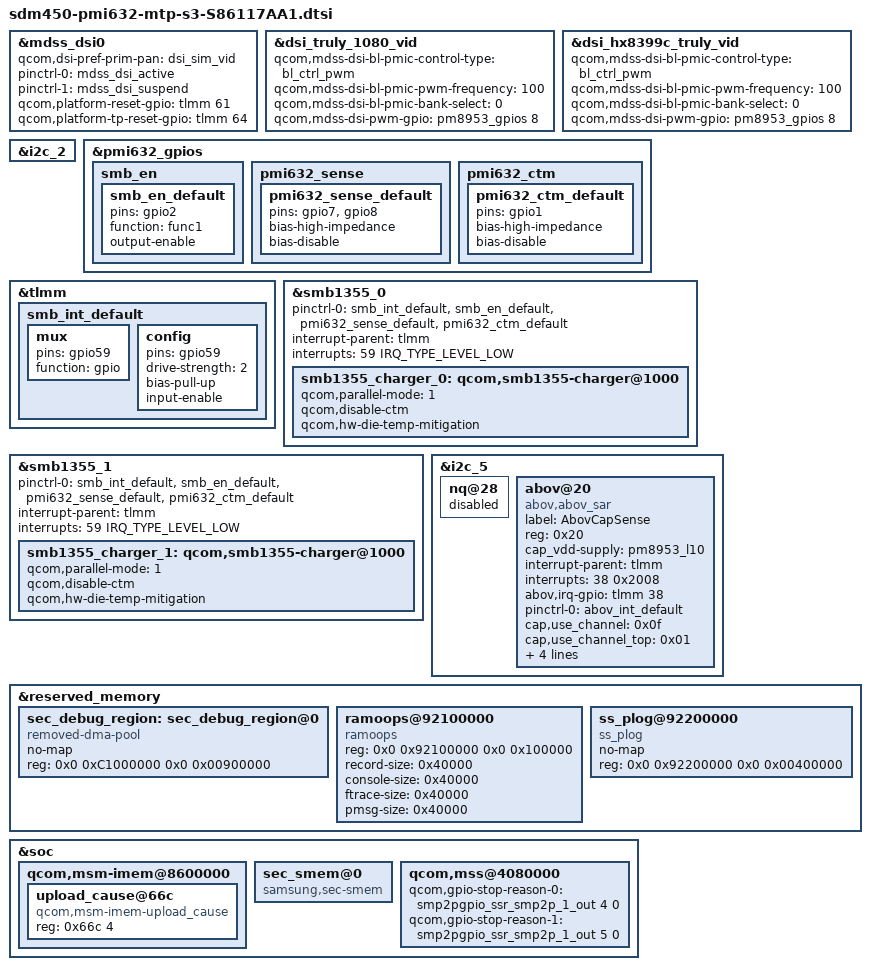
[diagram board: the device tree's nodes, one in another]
/*
 * Copyright (c) 2018-2019, The Linux Foundation. All rights reserved.
 *
 * This program is free software; you can redistribute it and/or modify
 * it under the terms of the GNU General Public License version 2 and
 * only version 2 as published by the Free Software Foundation.
 *
 * This program is distributed in the hope that it will be useful,
 * but WITHOUT ANY WARRANTY; without even the implied warranty of
 * MERCHANTABILITY or FITNESS FOR A PARTICULAR PURPOSE.  See the
 * GNU General Public License for more details.
 */

#include "msm8953-mtp.dtsi"

&mdss_dsi0 {
	qcom,dsi-pref-prim-pan = <&dsi_sim_vid>;
	pinctrl-names = "mdss_default", "mdss_sleep";
	pinctrl-0 = <&mdss_dsi_active>;
	pinctrl-1 = <&mdss_dsi_suspend>;
	//qcom,platform-bklight-en-gpio = <&pm8953_gpios 4 0>;
	qcom,platform-reset-gpio = <&tlmm 61 0>;
	qcom,platform-tp-reset-gpio = <&tlmm 64 0>;
};

&dsi_truly_1080_vid {
	qcom,mdss-dsi-bl-pmic-control-type = "bl_ctrl_pwm";
	qcom,mdss-dsi-bl-pmic-pwm-frequency = <100>;
	qcom,mdss-dsi-bl-pmic-bank-select = <0>;
	qcom,mdss-dsi-pwm-gpio = <&pm8953_gpios 8 0>;
};

&dsi_hx8399c_truly_vid {
	qcom,mdss-dsi-bl-pmic-control-type = "bl_ctrl_pwm";
	qcom,mdss-dsi-bl-pmic-pwm-frequency = <100>;
	qcom,mdss-dsi-bl-pmic-bank-select = <0>;
	qcom,mdss-dsi-pwm-gpio = <&pm8953_gpios 8 0>;
};

&i2c_2 {
#address-cells = <1>;
#size-cells = <0>;

#include "smb1355.dtsi"
};

&pmi632_gpios {
	smb_en {
		smb_en_default: smb_en_default {
			pins = "gpio2";
			function = "func1";
			output-enable;
		};
	};

	pmi632_sense {
		/* GPIO 7 and 8 are external-sense pins for PMI632 */
		pmi632_sense_default: pmi632_sense_default {
			pins = "gpio7", "gpio8";
			bias-high-impedance;	/* disable the GPIO */
			bias-disable;		/* no-pull */
		};
	};

	pmi632_ctm {
		/* Disable GPIO1 for h/w base mitigation */
		pmi632_ctm_default: pmi632_ctm_default {
			pins = "gpio1";
			bias-high-impedance;	/* disable the GPIO */
			bias-disable;		/* no-pull */
		};
	};
};

&tlmm {
	smb_int_default: smb_int_default {
		mux {
			pins = "gpio59";
			function = "gpio";
		};
		config {
			pins = "gpio59";
			drive-strength = <2>;
			bias-pull-up;
			input-enable;
		};
	};
};

&smb1355_0 {
	pinctrl-names = "default";
	pinctrl-0 = <&smb_int_default
		&smb_en_default &pmi632_sense_default &pmi632_ctm_default>;
	interrupt-parent = <&tlmm>;
	interrupts = <59 IRQ_TYPE_LEVEL_LOW>;
	smb1355_charger_0: qcom,smb1355-charger@1000 {
		status ="ok";
		/delete-property/ io-channels;
		/delete-property/ io-channels-names;
		qcom,parallel-mode = <1>;
		qcom,disable-ctm;
		qcom,hw-die-temp-mitigation;
	};
};

&smb1355_1 {
	pinctrl-names = "default";
	pinctrl-0 = <&smb_int_default
		&smb_en_default &pmi632_sense_default &pmi632_ctm_default>;
	interrupt-parent = <&tlmm>;
	interrupts = <59 IRQ_TYPE_LEVEL_LOW>;
	smb1355_charger_1: qcom,smb1355-charger@1000 {
		status ="ok";
		/delete-property/ io-channels;
		/delete-property/ io-channels-names;
		qcom,parallel-mode = <1>;
		qcom,disable-ctm;
		qcom,hw-die-temp-mitigation;
	};
};
&i2c_5 { /* BLSP2 QUP1 */
	status = "ok";
	nq@28 {
		status = "disabled";
	};
	abov@20 {
        label = "AbovCapSense";
        compatible = "abov,abov_sar";
        reg = <0x20>;
        cap_vdd-supply = <&pm8953_l10>;
        interrupt-parent = <&tlmm>;
        interrupts = <38 0x2008>;
        abov,irq-gpio = <&tlmm 38 0x2008>; /* IRQ */
        pinctrl-names = "abov_int_default";
        pinctrl-0 = <&abov_int_default>;
        cap,use_channel = <0x0f>;
        cap,use_channel_top = <0x01>;
        cap,use_channel_bottom = <0x00>;
        cap,scan_period = <0x02>;
        reg_array_len = <2>;
        reg_array_val = <0x18 0x5a 0x19 0x93>;
	};
};

&reserved_memory {
	/* CONFIG_SEC_DEBUG reserves 9MB */
	sec_debug_region: sec_debug_region@0 {
		  compatible = "removed-dma-pool";
		  no-map;
		  reg = <0x0 0xC1000000 0x0 0x00900000>;
	};

	ramoops@92100000 {
		  compatible = "ramoops";
		  reg = <0x0 0x92100000 0x0 0x100000>;
		  record-size = <0x40000>;
		  console-size = <0x40000>;
		  ftrace-size = <0x40000>;
		  pmsg-size = <0x40000>;
	};

	ss_plog@92200000 {
		compatible = "ss_plog";
		no-map;
		reg = <0x0 0x92200000 0x0 0x00400000>;
	};
};

&soc {
	qcom,msm-imem@8600000 {
		upload_cause@66c {
			compatible = "qcom,msm-imem-upload_cause";
			reg = <0x66c 4>;
		};
	};
	sec_smem@0 {
		compatible = "samsung,sec-smem";
		status = "okay";
	};
	qcom,mss@4080000 {
		/* GPIO output to mss */
		qcom,gpio-stop-reason-0 = <&smp2pgpio_ssr_smp2p_1_out 4 0>;
		qcom,gpio-stop-reason-1 = <&smp2pgpio_ssr_smp2p_1_out 5 0>;
	};
};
